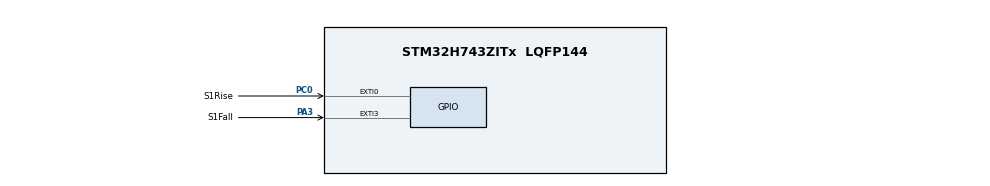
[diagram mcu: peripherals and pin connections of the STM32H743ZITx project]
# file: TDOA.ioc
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Mcu.Family=STM32H7
Mcu.Name=STM32H743ZITx
Mcu.Package=LQFP144
NVIC.EXTI0_IRQn=true\:0\:0\:false\:false\:true\:true\:true
NVIC.EXTI3_IRQn=true\:0\:0\:false\:false\:true\:true\:true
NVIC.PriorityGroup=NVIC_PRIORITYGROUP_4
PA11.Signal=UART4_RX
PA12.Signal=UART4_TX
PA3.GPIO_Label=S1Fall
PA3.GPIO_ModeDefaultEXTI=GPIO_MODE_IT_FALLING
PA3.Signal=GPXTI3
PB14.Signal=USART1_TX
PB15.Signal=USART1_RX
PC0.GPIO_Label=S1Rise
PC0.Signal=GPXTI0
ProjectManager.HeapSize=0x200
ProjectManager.StackSize=0x400
ProjectManager.TargetToolchain=STM32CubeIDE
RCC.ADCFreq_Value=129000000
RCC.APB1Freq_Value=120000000
RCC.APB2Freq_Value=120000000
RCC.APB3Freq_Value=120000000
RCC.APB4Freq_Value=120000000
RCC.CortexFreq_Value=480000000
RCC.D1PPRE=RCC_APB3_DIV2
RCC.D2PPRE1=RCC_APB1_DIV2
RCC.D2PPRE2=RCC_APB2_DIV2
RCC.D3PPRE=RCC_APB4_DIV2
RCC.DIVM1=4
RCC.DIVN1=60
RCC.HCLKFreq_Value=240000000
RCC.HPRE=RCC_HCLK_DIV2
RCC.PLL2FRACN=0
RCC.PLL3FRACN=0
RCC.PLLFRACN=0
RCC.SYSCLKFreq_VALUE=480000000
RCC.SYSCLKSource=RCC_SYSCLKSOURCE_PLLCLK
RCC.USBFreq_Value=480000000
VP_TIM2_VS_ClockSourceINT.Mode=Internal
board=custom

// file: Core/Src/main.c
/* USER CODE BEGIN Header */
/**
  ******************************************************************************
  * @file           : main.c
  * @brief          : Main program body
  ******************************************************************************
  * @attention
  *
  * <h2><center>&copy; Copyright (c) 2021 STMicroelectronics.
  * All rights reserved.</center></h2>
  *
  * This software component is licensed by ST under BSD 3-Clause license,
  * the "License"; You may not use this file except in compliance with the
  * License. You may obtain a copy of the License at:
  *                        opensource.org/licenses/BSD-3-Clause
  *
  ******************************************************************************
  */
/* USER CODE END Header */
#include "main.h"

/* USER CODE BEGIN PM */
//Possible states of the system
enum State{S1_Estimation, S2_Estimation, S3_Estimation, PairPhase, Transmit};
/* USER CODE END PM */

TIM_HandleTypeDef htim2;

/* USER CODE BEGIN PV */
//Current state of the system
enum State state = S1_Estimation;

//Timestamp datastructures for the sensors
Timestamps ts1;
Timestamps ts2;
Timestamps ts3;

//Current sensor that is sampling
uint8_t samplingSensor = 0;

//Period in samples of one wavelength
double period = 6263;
double periodS[3];

//Middle points of rising and falling edge for sensors
uint32_t midPoints1[SAMPLE_SIZE-1];
uint32_t midPoints2[SAMPLE_SIZE-1];
uint32_t midPoints3[SAMPLE_SIZE-1];

//Shift of middle points
double midPointShift[SAMPLE_SIZE-1];

//Midpoint smart selection variables
uint16_t cntRising = 0;
uint16_t cntFalling = 0;
uint16_t midPointCount = 0;
uint16_t dist;

//Average shift of the different sensors
double meanShiftS1;
double meanShiftS2;
double meanShiftS3;

//Time difference of arrival
double TDOA12;
double TDOA13;

double TDOA12mean;
double TDOA13mean;
uint16_t TDOACount;
/* USER CODE END PV */

void SystemClock_Config(void);
static void MX_GPIO_Init(void);
static void MX_TIM2_Init(void);
void Get_Mid_Points(Timestamps* t, uint32_t* midpoints);

int main(void)
{
  /* USER CODE BEGIN 1 */
	ts = &ts1;
  /* USER CODE END 1 */

  /* MCU Configuration--------------------------------------------------------*/

  /* Reset of all peripherals, Initializes the Flash interface and the Systick. */
  HAL_Init();

  /* USER CODE BEGIN Init */
  HAL_NVIC_DisableIRQ(EXTI0_IRQn);
  HAL_NVIC_DisableIRQ(EXTI3_IRQn);
  /* USER CODE END Init */

  /* Configure the system clock */
  SystemClock_Config();

  /* Initialize all configured peripherals */
  MX_GPIO_Init();
  MX_TIM2_Init();
  /* USER CODE BEGIN 2 */
  __HAL_TIM_ENABLE(&htim2);
  HAL_NVIC_EnableIRQ(EXTI0_IRQn);
  HAL_NVIC_EnableIRQ(EXTI3_IRQn);
  /* USER CODE END 2 */

  /* Infinite loop */
  /* USER CODE BEGIN WHILE */
  while (1)
  {
	  switch(state){
	  	  case S1_Estimation:
	  		  if(ts1.riseCount == SAMPLE_SIZE && ts1.fallCount == SAMPLE_SIZE){

	  			  Get_Mid_Points(&ts1, midPoints1);
	  			  for(int i = 0; i < midPointCount-1; i++){
	  				  periodS[0] = periodS[0] + midPoints1[i+1] - midPoints1[i];
	  			  }
	  			  periodS[0] = periodS[0]/(midPointCount-1);
	  			  for(int i = 0; i < midPointCount;i++){
	  				  midPointShift[i] = fmod(midPoints1[i]+period/2,period)-period/2;
	  				  meanShiftS1 = meanShiftS1 + midPointShift[i] / midPointCount;
	  			  }

	  			  state = S2_Estimation;
	  		  }
	  		  break;
	  	  case S2_Estimation:
	  		  if(ts2.riseCount == SAMPLE_SIZE && ts2.fallCount == SAMPLE_SIZE){
	  			  Get_Mid_Points(&ts2,midPoints2);

	  			  for(int i = 0; i < midPointCount-1; i++){
	  				  periodS[1] = periodS[1] + midPoints2[i+1] - midPoints2[i];
	  			  }
	  			  periodS[1] = periodS[1]/(midPointCount-1);

	  			  for(int i = 0; i < midPointCount;i++){
	  				  midPointShift[i] = fmod(midPoints2[i]+period/2,period)-period/2;
	  				  meanShiftS2 = meanShiftS2 + midPointShift[i] / midPointCount;
	  			  }

	  			  state = S3_Estimation;
	  		  }
	  		  break;

	  	  case S3_Estimation:
	  		  if(ts3.riseCount == SAMPLE_SIZE && ts3.fallCount == SAMPLE_SIZE){

	  			  Get_Mid_Points(&ts3,midPoints3);

	  			  for(int i = 0; i < midPointCount-1; i++){
	  				  periodS[2] = periodS[2] + midPoints3[i+1] - midPoints3[i];
				  }
				  periodS[2] = periodS[2]/(midPointCount-1);

	  			  for(int i = 0; i < midPointCount;i++){
	  				  midPointShift[i] = fmod(midPoints3[i]+period/2,period)-period/2;
	  				  meanShiftS3 = meanShiftS3 + midPointShift[i] / midPointCount;
	  			  }
	  			  state = PairPhase;
	  		  }
	  		  break;
	  	  case PairPhase:
	  		  TDOA12 = fmod(meanShiftS2-meanShiftS1+period/2,period) - period/2;
	  		  TDOA13 = fmod(meanShiftS3-meanShiftS1+period/2,period) - period/2;
	  		  TDOA12mean = TDOA12mean + TDOA12;
	  		  TDOA13mean = TDOA13mean + TDOA13;
	  		  TDOACount = TDOACount + 1;
	  		  if(TDOACount == 3){
	  			  TDOA12mean = TDOA12mean/3;
	  			  TDOA13mean = TDOA13mean/3;
	  			  TDOACount = 0;
	  			  TDOA12mean = 0;
	  			  TDOA13mean = 0;
	  		  }
	  		  state = Transmit;
	  		  break;
	  	  case Transmit:

	  		  state = S1_Estimation;
	  		  meanShiftS1 = 0;
	  		  meanShiftS2 = 0;
	  		  meanShiftS3 = 0;
	  		  ts1.riseCount = 0;
	  		  ts1.fallCount = 0;
	  		  ts2.riseCount = 0;
	  		  ts2.fallCount = 0;
			  ts3.riseCount = 0;
			  ts3.fallCount = 0;
//			  __HAL_RCC_TIM2_FORCE_RESET();
//			  MX_TIM2_Init();
//			  __HAL_TIM_ENABLE(&htim2);
	  		  //Turn on interrupts
	  		  break;
  	  }

    /* USER CODE END WHILE */

  }
}

void SystemClock_Config(void)
{
  RCC_OscInitTypeDef RCC_OscInitStruct = {0};
  RCC_ClkInitTypeDef RCC_ClkInitStruct = {0};

  /** Supply configuration update enable
  */
  HAL_PWREx_ConfigSupply(PWR_LDO_SUPPLY);
  /** Configure the main internal regulator output voltage
  */
  __HAL_PWR_VOLTAGESCALING_CONFIG(PWR_REGULATOR_VOLTAGE_SCALE0);

  while(!__HAL_PWR_GET_FLAG(PWR_FLAG_VOSRDY)) {}
  /** Initializes the RCC Oscillators according to the specified parameters
  * in the RCC_OscInitTypeDef structure.
  */
  RCC_OscInitStruct.OscillatorType = RCC_OSCILLATORTYPE_HSI;
  RCC_OscInitStruct.HSIState = RCC_HSI_DIV1;
  RCC_OscInitStruct.HSICalibrationValue = RCC_HSICALIBRATION_DEFAULT;
  RCC_OscInitStruct.PLL.PLLState = RCC_PLL_ON;
  RCC_OscInitStruct.PLL.PLLSource = RCC_PLLSOURCE_HSI;
  RCC_OscInitStruct.PLL.PLLM = 4;
  RCC_OscInitStruct.PLL.PLLN = 60;
  RCC_OscInitStruct.PLL.PLLP = 2;
  RCC_OscInitStruct.PLL.PLLQ = 2;
  RCC_OscInitStruct.PLL.PLLR = 2;
  RCC_OscInitStruct.PLL.PLLRGE = RCC_PLL1VCIRANGE_3;
  RCC_OscInitStruct.PLL.PLLVCOSEL = RCC_PLL1VCOWIDE;
  RCC_OscInitStruct.PLL.PLLFRACN = 0;
  if (HAL_RCC_OscConfig(&RCC_OscInitStruct) != HAL_OK)
  {
    Error_Handler();
  }
  /** Initializes the CPU, AHB and APB buses clocks
  */
  RCC_ClkInitStruct.ClockType = RCC_CLOCKTYPE_HCLK|RCC_CLOCKTYPE_SYSCLK
                              |RCC_CLOCKTYPE_PCLK1|RCC_CLOCKTYPE_PCLK2
                              |RCC_CLOCKTYPE_D3PCLK1|RCC_CLOCKTYPE_D1PCLK1;
  RCC_ClkInitStruct.SYSCLKSource = RCC_SYSCLKSOURCE_PLLCLK;
  RCC_ClkInitStruct.SYSCLKDivider = RCC_SYSCLK_DIV1;
  RCC_ClkInitStruct.AHBCLKDivider = RCC_HCLK_DIV2;
  RCC_ClkInitStruct.APB3CLKDivider = RCC_APB3_DIV2;
  RCC_ClkInitStruct.APB1CLKDivider = RCC_APB1_DIV2;
  RCC_ClkInitStruct.APB2CLKDivider = RCC_APB2_DIV2;
  RCC_ClkInitStruct.APB4CLKDivider = RCC_APB4_DIV2;

  if (HAL_RCC_ClockConfig(&RCC_ClkInitStruct, FLASH_LATENCY_4) != HAL_OK)
  {
    Error_Handler();
  }
}

static void MX_TIM2_Init(void)
{

  TIM_ClockConfigTypeDef sClockSourceConfig = {0};
  TIM_MasterConfigTypeDef sMasterConfig = {0};

  htim2.Instance = TIM2;
  htim2.Init.Prescaler = 0;
  htim2.Init.CounterMode = TIM_COUNTERMODE_UP;
  htim2.Init.Period = 4294967295;
  htim2.Init.ClockDivision = TIM_CLOCKDIVISION_DIV1;
  htim2.Init.AutoReloadPreload = TIM_AUTORELOAD_PRELOAD_DISABLE;
  if (HAL_TIM_Base_Init(&htim2) != HAL_OK)
  {
    Error_Handler();
  }
  sClockSourceConfig.ClockSource = TIM_CLOCKSOURCE_INTERNAL;
  if (HAL_TIM_ConfigClockSource(&htim2, &sClockSourceConfig) != HAL_OK)
  {
    Error_Handler();
  }
  sMasterConfig.MasterOutputTrigger = TIM_TRGO_RESET;
  sMasterConfig.MasterSlaveMode = TIM_MASTERSLAVEMODE_DISABLE;
  if (HAL_TIMEx_MasterConfigSynchronization(&htim2, &sMasterConfig) != HAL_OK)
  {
    Error_Handler();
  }

}

static void MX_GPIO_Init(void)
{
  GPIO_InitTypeDef GPIO_InitStruct = {0};

  /* GPIO Ports Clock Enable */
  __HAL_RCC_GPIOC_CLK_ENABLE();
  __HAL_RCC_GPIOA_CLK_ENABLE();
  __HAL_RCC_GPIOB_CLK_ENABLE();

  /*Configure GPIO pin : S1Rise_Pin */
  GPIO_InitStruct.Pin = S1Rise_Pin;
  GPIO_InitStruct.Mode = GPIO_MODE_IT_RISING;
  GPIO_InitStruct.Pull = GPIO_NOPULL;
  HAL_GPIO_Init(S1Rise_GPIO_Port, &GPIO_InitStruct);

  /*Configure GPIO pin : S1Fall_Pin */
  GPIO_InitStruct.Pin = S1Fall_Pin;
  GPIO_InitStruct.Mode = GPIO_MODE_IT_FALLING;
  GPIO_InitStruct.Pull = GPIO_NOPULL;
  HAL_GPIO_Init(S1Fall_GPIO_Port, &GPIO_InitStruct);

  /*Configure GPIO pins : PB14 PB15 */
  GPIO_InitStruct.Pin = GPIO_PIN_14|GPIO_PIN_15;
  GPIO_InitStruct.Mode = GPIO_MODE_AF_PP;
  GPIO_InitStruct.Pull = GPIO_NOPULL;
  GPIO_InitStruct.Speed = GPIO_SPEED_FREQ_LOW;
  GPIO_InitStruct.Alternate = GPIO_AF4_USART1;
  HAL_GPIO_Init(GPIOB, &GPIO_InitStruct);

  /*Configure GPIO pins : PA11 PA12 */
  GPIO_InitStruct.Pin = GPIO_PIN_11|GPIO_PIN_12;
  GPIO_InitStruct.Mode = GPIO_MODE_AF_PP;
  GPIO_InitStruct.Pull = GPIO_NOPULL;
  GPIO_InitStruct.Speed = GPIO_SPEED_FREQ_LOW;
  GPIO_InitStruct.Alternate = GPIO_AF6_UART4;
  HAL_GPIO_Init(GPIOA, &GPIO_InitStruct);

  /* EXTI interrupt init*/
  HAL_NVIC_SetPriority(EXTI0_IRQn, 0, 0);
  HAL_NVIC_EnableIRQ(EXTI0_IRQn);

  HAL_NVIC_SetPriority(EXTI3_IRQn, 0, 0);
  HAL_NVIC_EnableIRQ(EXTI3_IRQn);

}

/* USER CODE BEGIN 4 */
void Sensor_Multiplex_Control(void){
	if(ts->fallCount == SAMPLE_SIZE && ts->riseCount == SAMPLE_SIZE)
	{
		switch(samplingSensor){
		case 0:
			samplingSensor = 1;
			//Switch Multiplexer
			ts = &ts2;
			//HAL_NVIC_EnableIRQ(EXTI0_IRQn);
			//HAL_NVIC_EnableIRQ(EXTI3_IRQn);
			break;
		case 1:
			samplingSensor = 2;
			//Switch Multiplexer
			ts = &ts3;
			//HAL_NVIC_EnableIRQ(EXTI0_IRQn);
			//HAL_NVIC_EnableIRQ(EXTI3_IRQn);
			break;
		case 2:
			samplingSensor = 0;
			ts = &ts1;
			//Switch Multiplexer
			break;
		}
	}
}

void Get_Mid_Points(Timestamps* t, uint32_t* midpoints){
	cntRising = 1;
	cntFalling = 1;
	midPointCount = 0;
	while(cntRising <= SAMPLE_SIZE-1 && cntFalling < SAMPLE_SIZE-1){
		dist = t->fallStamps[cntFalling] - t->riseStamps[cntRising];
		while(dist < 0 && t->fallStamps[cntFalling] < SAMPLE_SIZE-1){
			cntFalling = cntFalling + 1;
			dist = t->fallStamps[cntFalling] - t->riseStamps[cntRising];
		}

		while(cntFalling < SAMPLE_SIZE-1 && t->fallStamps[cntFalling+1] - t->riseStamps[cntRising] <= dist){
			cntFalling = cntFalling + 1;
			dist = t->fallStamps[cntFalling] - t->riseStamps[cntRising];
		}
		if(dist >= 0){
			midpoints[midPointCount] = t->riseStamps[cntRising] + dist/2;
			if(cntRising < SAMPLE_SIZE-1 && cntFalling < SAMPLE_SIZE-1){
				cntRising = cntRising + 1;
				midPointCount = midPointCount + 1;
			}
		}

	}
}

/* USER CODE END 4 */

void Error_Handler(void)
{
  __disable_irq();
  while (1)
  {
  }
}

/************************ (C) COPYRIGHT STMicroelectronics *****END OF FILE****/
